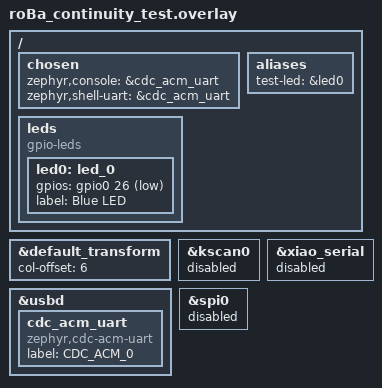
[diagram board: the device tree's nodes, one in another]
/*
 * Simple continuity test overlay
 * Automatically cycles through pins and reports via USB serial
 */

#include "roBa.dtsi"

&default_transform {
    col-offset = <6>;
};

// Disable keyboard scanning
&kscan0 {
    status = "disabled";
};

// Enable USB CDC for serial communication
&usbd {
    status = "okay";
    cdc_acm_uart: cdc_acm_uart {
        compatible = "zephyr,cdc-acm-uart";
        label = "CDC_ACM_0";
    };
};

/ {
    chosen {
        zephyr,console = &cdc_acm_uart;
        zephyr,shell-uart = &cdc_acm_uart;
    };
    
    // Test configuration
    aliases {
        test-led = &led0;
    };
    
    leds {
        compatible = "gpio-leds";
        led0: led_0 {
            gpios = <&gpio0 26 GPIO_ACTIVE_LOW>;
            label = "Blue LED";
        };
    };
};

// Disable other peripherals for testing
&xiao_serial { status = "disabled"; };
&spi0 { status = "disabled"; };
